# EFM32GG12B810F1024GL112 register map
File version: 4.0.0
CPU: CM4 r0p1, little endian, MPU, FPU, 3 interrupt priority bits
Registers are 32-bit, read-write, reset 0x0 unless marked. A register's access mark holds for its fields unless they carry their own. Offsets are from the block's base; [hi:lo] are bit positions; {n}, {i} and the like mark numbered series; 'fields as' and 'values as' point back to an identical list.

## USB
Base 0x40022000
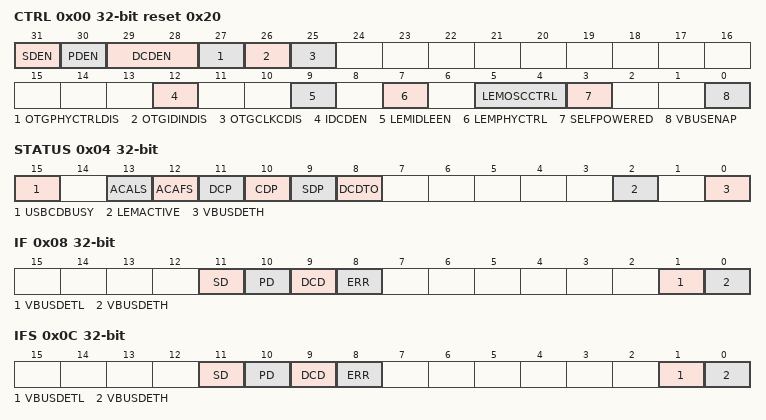
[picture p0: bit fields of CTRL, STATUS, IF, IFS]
0x00 CTRL reset 0x20 — System Control Register
  [31] SDEN — Secondary Detection Enable
  [30] PDEN — Primary Detection Enable
  [29:28] DCDEN — Data Contact Detection Enable
    0=DISABLED (DCD is disabled.); 2=TIMEOUT (Only DCD timeout will be initiated.); 3=ENABLED (Full DCD operation (physical contact and timeout) will be initiated.)
  [27] OTGPHYCTRLDIS — OTG Control Signals to PHY Disable
  [26] OTGIDINDIS — OTG ID Input Disable
  [25] OTGCLKCDIS — OTG CLKC Disable
  [12] IDCDEN — ID Pull-up Enable
  [9] LEMIDLEEN — Low Energy Mode on Bus Idle Enable
  [7] LEMPHYCTRL — Low Energy Mode USB PHY Control
  [5:4] LEMOSCCTRL — Low Energy Mode Oscillator Control
    0=NONE (Low Energy Mode has no effect on neither USBC or USHFRCO.); 1=GATE (The USBC clock is gated when Low Energy Mode is active.)
  [3] SELFPOWERED — PHY Power
  [0] VBUSENAP — VBUSEN Active Polarity
0x04 STATUS ro — System Status Register
  [15] USBCDBUSY — USB Charger Detect Busy
  [13] ACALS — ACA Low Speed TypeB Device
  [12] ACAFS — ACA Full Speed TypeB Device
  [11] DCP — Dedicated Charging Port Detected
  [10] CDP — Charging Downstream Port Detected
  [9] SDP — Standard Downstream Port Detected
  [8] DCDTO — Data Contact Detection Timeout
  [2] LEMACTIVE — Low Energy Mode Active
  [0] VBUSDETH — VBUS Detect High
0x08 IF ro — Interrupt Flag Register
  [11] SD — Secondary Detection Complete Interrupt Flag
  [10] PD — Primary Detection Complete Interrupt Flag
  [9] DCD — Data Contact Detection Complete Interrupt Flag
  [8] ERR — Detection Error Interrupt Flag
  [1] VBUSDETL — VBUS Detect Low Interrupt Flag
  [0] VBUSDETH — VBUS Detect High Interrupt Flag
0x0C IFS wo — Interrupt Flag Set Register
  [11] SD — Set SD Interrupt Flag
  [10] PD — Set PD Interrupt Flag
  [9] DCD — Set DCD Interrupt Flag
  [8] ERR — Set ERR Interrupt Flag
  [1] VBUSDETL — Set VBUSDETL Interrupt Flag
  [0] VBUSDETH — Set VBUSDETH Interrupt Flag
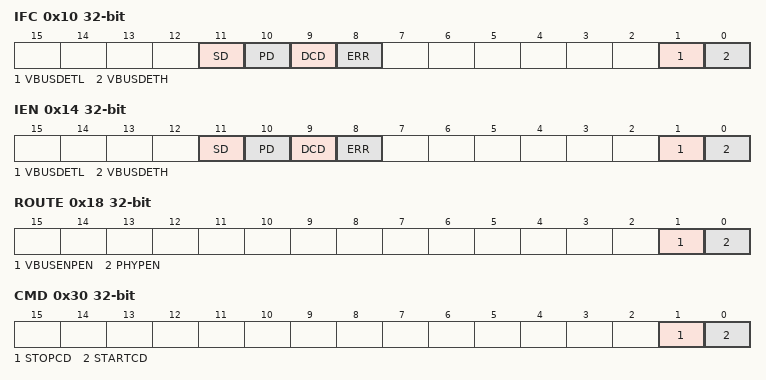
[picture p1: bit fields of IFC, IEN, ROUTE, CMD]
0x10 IFC wo — Interrupt Flag Clear Register
  [11] SD — Clear SD Interrupt Flag
  [10] PD — Clear PD Interrupt Flag
  [9] DCD — Clear DCD Interrupt Flag
  [8] ERR — Clear ERR Interrupt Flag
  [1] VBUSDETL — Clear VBUSDETL Interrupt Flag
  [0] VBUSDETH — Clear VBUSDETH Interrupt Flag
0x14 IEN — Interrupt Enable Register
  [11] SD — SD Interrupt Enable
  [10] PD — PD Interrupt Enable
  [9] DCD — DCD Interrupt Enable
  [8] ERR — ERR Interrupt Enable
  [1] VBUSDETL — VBUSDETL Interrupt Enable
  [0] VBUSDETH — VBUSDETH Interrupt Enable
0x18 ROUTE — I/O Routing Register
  [1] VBUSENPEN — VBUSEN Pin Enable
  [0] PHYPEN — USB PHY Pin Enable
0x2C CDCONF — Charger Detect Configuration Register
  [9:0] DCDTOCONF — DCD Timeout (TDCD_TIMEOUT) Configuration
0x30 CMD wo — Command Register
  [1] STOPCD — Start Charger Detection in Progress
  [0] STARTCD — Start Charger Detection Enabled
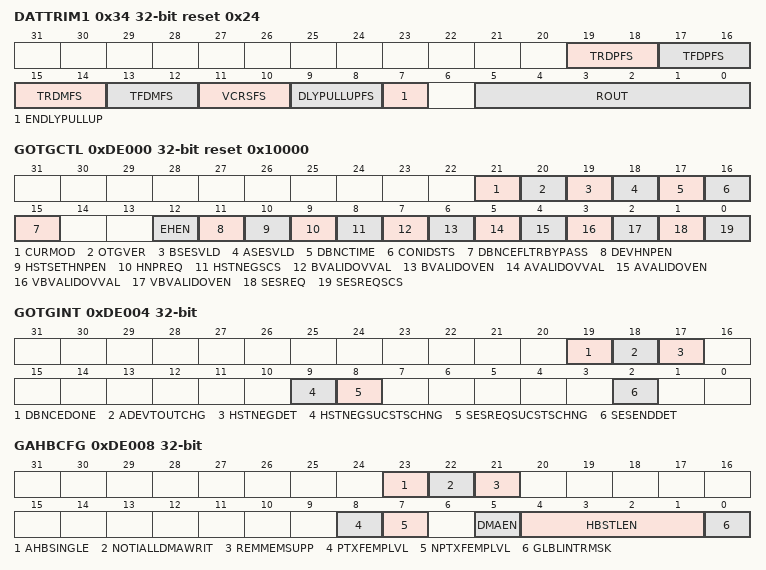
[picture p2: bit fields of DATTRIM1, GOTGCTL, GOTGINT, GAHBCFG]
0x34 DATTRIM1 reset 0x24 — Data TRIM 1 Values for USB DP and DM
  [19:18] TRDPFS — Trim for DP Rise Time in FS
  [17:16] TFDPFS — Trim for DP Fall Time in FS
  [15:14] TRDMFS — Trim for DM Rise Time in FS
  [13:12] TFDMFS — Trim for DM Fall Time in FS
  [11:10] VCRSFS — Trim for Falling Crossover Voltage in FS
  [9:8] DLYPULLUPFS — Trim for Rising Crossover Voltage in FS
  [7] ENDLYPULLUP — Enables Delay of Pull in TX Mode for Both FS and LS
  [5:0] ROUT — Trim for DP and DM Output Impedance for Both FS and LS
0x3C LEMCTRL reset 0x67 — USB LEM Control Register
  [9:0] TIMEBASE — Set the Number of LFC Clk Counts to Form 3ms
0x40 ROUTELOC0 — I/O Routing Location Register
  [5:0] VBUSENPENLOC — I/O Location
    0=LOC0 (Location 0); 1=LOC1 (Location 1); 2=LOC2 (Location 2)
0xDE000 GOTGCTL reset 0x10000 — OTG Control and Status Register
  [21] CURMOD ro — Current Mode of Operation
  [20] OTGVER — OTG Version
  [19] BSESVLD ro — B-Session Valid
  [18] ASESVLD ro — A-Session Valid
  [17] DBNCTIME ro — Long/Short Debounce Time
  [16] CONIDSTS ro — Connector ID Status
  [15] DBNCEFLTRBYPASS — Debounce Filter Bypass
  [12] EHEN — Embedded Host Enable
  [11] DEVHNPEN — Device HNP Enabled
  [10] HSTSETHNPEN — Host Set HNP Enable
  [9] HNPREQ — HNP Request
  [8] HSTNEGSCS ro — Host Negotiation Success
  [7] BVALIDOVVAL — B-Peripheral Session Valid OverrideValue
  [6] BVALIDOVEN — B-Peripheral Session Valid Override Enable
  [5] AVALIDOVVAL — A-Peripheral Session Valid OverrideValue
  [4] AVALIDOVEN — A-Peripheral Session Valid Override Enable
  [3] VBVALIDOVVAL — VBUS Valid OverrideValue
  [2] VBVALIDOVEN — VBUS Valid Override Enable
  [1] SESREQ — Session Request
  [0] SESREQSCS ro — Session Request Success
0xDE004 GOTGINT — OTG Interrupt Register
  [19] DBNCEDONE — Debounce Done
  [18] ADEVTOUTCHG — A-Device Timeout Change
  [17] HSTNEGDET — Host Negotiation Detected
  [9] HSTNEGSUCSTSCHNG — Host Negotiation Success Status Change
  [8] SESREQSUCSTSCHNG — Session Request Success Status Change
  [2] SESENDDET — Session End Detected
0xDE008 GAHBCFG — AHB Configuration Register
  [23] AHBSINGLE — AHB Single Support
  [22] NOTIALLDMAWRIT — Notify All Dma Write Transactions
  [21] REMMEMSUPP — Remote Memory Support
  [8] PTXFEMPLVL — Periodic TxFIFO Empty Level
  [7] NPTXFEMPLVL — Non-Periodic TxFIFO Empty Level
  [5] DMAEN — DMA Enable
  [4:1] HBSTLEN — Burst Length/Type
    0=SINGLE (Single transfer.); 1=INCR (Incrementing burst of unspecified length.); 3=INCR4 (4-beat incrementing burst.); 5=INCR8 (8-beat incrementing burst.); 7=INCR16 (16-beat incrementing burst.)
  [0] GLBLINTRMSK — Global Interrupt Mask
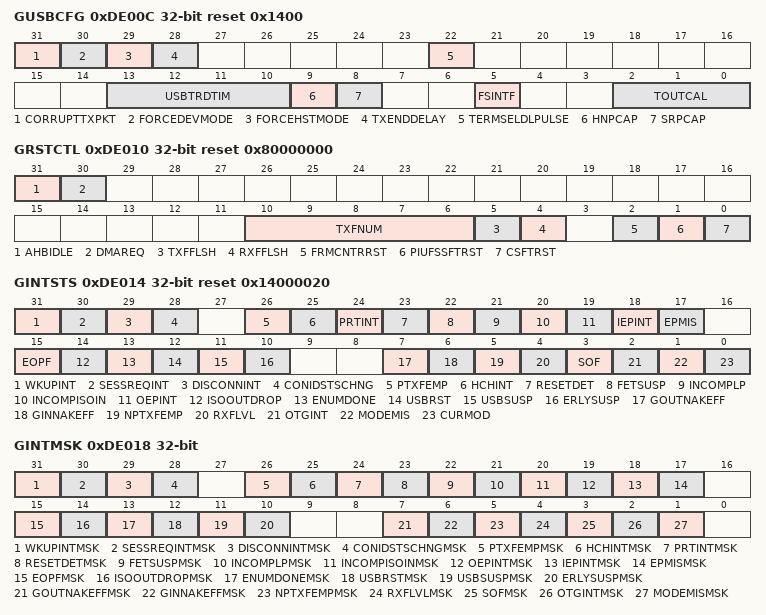
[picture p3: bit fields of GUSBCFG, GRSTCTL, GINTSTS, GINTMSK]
0xDE00C GUSBCFG reset 0x1400 — USB Configuration Register
  [31] CORRUPTTXPKT wo — Corrupt Tx packet (host and device)
  [30] FORCEDEVMODE — Force Device Mode
  [29] FORCEHSTMODE — Force Host Mode
  [28] TXENDDELAY
  [22] TERMSELDLPULSE — TermSel DLine Pulsing Selection
  [13:10] USBTRDTIM — USB Turnaround Time
  [9] HNPCAP — HNP-Capable
  [8] SRPCAP — SRP-Capable
  [5] FSINTF — Full-Speed Serial Interface Select
  [2:0] TOUTCAL — Timeout Calibration (host and device)
0xDE010 GRSTCTL reset 0x80000000 — Reset Register
  [31] AHBIDLE ro — AHB Master Idle
  [30] DMAREQ ro — DMA Request Signal
  [10:6] TXFNUM — TxFIFO Number (host and device)
    0=F0 (Host mode: Non-periodic TxFIFO flush. Device: Tx FIFO 0 flush); 1=F1 (Host mode: Periodic TxFIFO flush. Device: TXFIFO 1 flush.); {v}=F{v} (Device mode: TXFIFO {v} flush.) (v=2..6); 16=FALL (Flush all the transmit FIFOs in device or host mode.)
  [5] TXFFLSH — TxFIFO Flush
  [4] RXFFLSH — RxFIFO Flush
  [2] FRMCNTRRST — Host Frame Counter Reset
  [1] PIUFSSFTRST — PIU FS Dedicated Controller Soft Reset
  [0] CSFTRST — Core Soft Reset (host and device)
0xDE014 GINTSTS reset 0x14000020 — Interrupt Register
  [31] WKUPINT — Resume/Remote Wakeup Detected Interrupt (host and device)
  [30] SESSREQINT — Session Request/New Session Detected Interrupt (host and device)
  [29] DISCONNINT — Disconnect Detected Interrupt (host only)
  [28] CONIDSTSCHNG — Connector ID Status Change (host and device)
  [26] PTXFEMP ro — Periodic TxFIFO Empty (host only)
  [25] HCHINT ro — Host Channels Interrupt (host only)
  [24] PRTINT ro — Host Port Interrupt (host only)
  [23] RESETDET — Reset detected Interrupt (device only)
  [22] FETSUSP — Data Fetch Suspended (device only)
  [21] INCOMPLP — Incomplete Periodic Transfer (device only)
  [20] INCOMPISOIN — Incomplete Isochronous IN Transfer (device only)
  [19] OEPINT ro — OUT Endpoints Interrupt (device only)
  [18] IEPINT ro — IN Endpoints Interrupt (device only)
  [17] EPMIS — Endpoint Mismatch Interrupt (device only)
  [15] EOPF — End of Periodic Frame Interrupt
  [14] ISOOUTDROP — Isochronous OUT Packet Dropped Interrupt (device only)
  [13] ENUMDONE — Enumeration Done (device only)
  [12] USBRST — USB Reset (device only)
  [11] USBSUSP — USB Suspend (device only)
  [10] ERLYSUSP — Early Suspend (device only)
  [7] GOUTNAKEFF ro — Global OUT NAK Effective (device only)
  [6] GINNAKEFF ro — Global IN Non-periodic NAK Effective (device only)
  [5] NPTXFEMP ro — Non-Periodic TxFIFO Empty (host only)
  [4] RXFLVL ro — RxFIFO Non-Empty (host and device)
  [3] SOF — Start of Frame (host and device)
  [2] OTGINT ro — OTG Interrupt (host and device)
  [1] MODEMIS — Mode Mismatch Interrupt (host and device)
  [0] CURMOD ro — Current Mode of Operation (host and device)
0xDE018 GINTMSK — Interrupt Mask Register
  [31] WKUPINTMSK — Resume/Remote Wakeup Detected Interrupt Mask (host and device)
  [30] SESSREQINTMSK — Session Request/New Session Detected Interrupt Mask (host and device)
  [29] DISCONNINTMSK — Disconnect Detected Interrupt Mask (host and device)
  [28] CONIDSTSCHNGMSK — Connector ID Status Change Mask (host and device)
  [26] PTXFEMPMSK — Periodic TxFIFO Empty Mask (host only)
  [25] HCHINTMSK — Host Channels Interrupt Mask (host only)
  [24] PRTINTMSK — Host Port Interrupt Mask (host only)
  [23] RESETDETMSK — Reset detected Interrupt Mask (device only)
  [22] FETSUSPMSK — Data Fetch Suspended Mask (device only)
  [21] INCOMPLPMSK — Incomplete Periodic Transfer Mask (host only)
  [20] INCOMPISOINMSK — Incomplete Isochronous IN Transfer Mask (device only)
  [19] OEPINTMSK — OUT Endpoints Interrupt Mask (device only)
  [18] IEPINTMSK — IN Endpoints Interrupt Mask (device only)
  [17] EPMISMSK — Endpoint Mismatch Interrupt Mask (device only)
  [15] EOPFMSK — End of Periodic Frame Interrupt Mask (device only)
  [14] ISOOUTDROPMSK — Isochronous OUT Packet Dropped Interrupt Mask (device only)
  [13] ENUMDONEMSK — Enumeration Done Mask (device only)
  [12] USBRSTMSK — USB Reset Mask (device only)
  [11] USBSUSPMSK — USB Suspend Mask (device only)
  [10] ERLYSUSPMSK — Early Suspend Mask (device only)
  [7] GOUTNAKEFFMSK — Global OUT NAK Effective Mask (device only)
  [6] GINNAKEFFMSK — Global Non-periodic IN NAK Effective Mask (device only)
  [5] NPTXFEMPMSK — Non-Periodic TxFIFO Empty Mask (host only)
  [4] RXFLVLMSK — Receive FIFO Non-Empty Mask (host and device)
  [3] SOFMSK — Start of Frame Mask (host and device)
  [2] OTGINTMSK — OTG Interrupt Mask (host and device)
  [1] MODEMISMSK — Mode Mismatch Interrupt Mask (host and device)
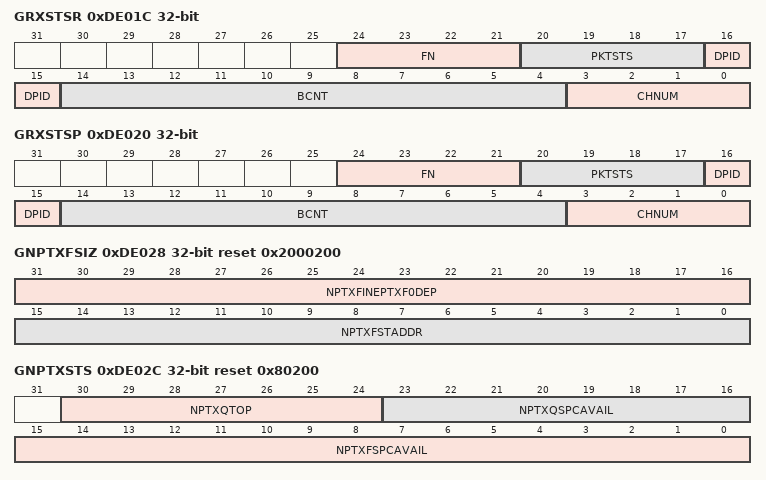
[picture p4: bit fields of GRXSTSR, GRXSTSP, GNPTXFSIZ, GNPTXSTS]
0xDE01C GRXSTSR ro — Receive Status Debug Read Register
  [24:21] FN — Frame Number
  [20:17] PKTSTS — Packet Status
    1=GOUTNAK (Device mode: Global OUT NAK (triggers an interrupt).); 2=PKTRCV (Host mode: IN data packet received. Device mode: OUT data packet received.); 3=XFERCOMPL (Host mode: IN transfer completed (triggers an interrupt). Device mode: OUT transfer completed (triggers an interrupt).); 4=SETUPCOMPL (Device mode: SETUP transaction completed (triggers an interrupt).); 5=TGLERR (Host mode: Data toggle error (triggers an interrupt).); 6=SETUPRCV (Device mode: SETUP data packet received.); 7=CHLT (Host mode: Channel halted (triggers an interrupt).)
  [16:15] DPID — Data PID
    0=DATA0 (DATA0 PID.); 1=DATA1 (DATA1 PID.); 2=DATA2 (DATA2 PID.); 3=MDATA (MDATA PID.)
  [14:4] BCNT — Byte Count
  [3:0] CHNUM — Channel Number
0xDE020 GRXSTSP ro — Receive Status Read /Pop Register
  [24:21] FN — Frame Number
  [20:17] PKTSTS — Packet Status (host or device)
    values as GRXSTSR.PKTSTS
  [16:15] DPID — Data PID (host or device)
    values as GRXSTSR.DPID
  [14:4] BCNT — Byte Count
  [3:0] CHNUM — Channel Number
0xDE024 GRXFSIZ reset 0x200 — Receive FIFO Size Register
  [9:0] RXFDEP — RxFIFO Depth
0xDE028 GNPTXFSIZ reset 0x2000200 — Non-periodic Transmit FIFO Size Register
  [31:16] NPTXFINEPTXF0DEP — Non-periodic TxFIFO Depth (host only) / IN Endpoint TxFIFO 0 Depth (device only)
  [15:0] NPTXFSTADDR — Non-periodic Transmit RAM Start Address
0xDE02C GNPTXSTS ro reset 0x80200 — Non-periodic Transmit FIFO/Queue Status Register
  [30:24] NPTXQTOP — Top of the Non-periodic Transmit Request Queue
  [23:16] NPTXQSPCAVAIL — Non-periodic Transmit Request Queue Space Available
  [15:0] NPTXFSPCAVAIL — Non-periodic TxFIFO Space Avail
0xDE040 GSNPSID ro reset 0x4F54330A — Synopsys ID Register
  [31:0] SYNOPSYSID
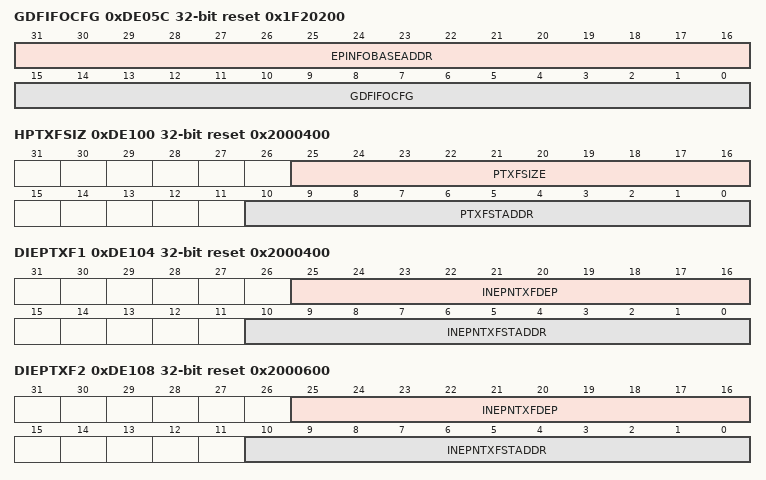
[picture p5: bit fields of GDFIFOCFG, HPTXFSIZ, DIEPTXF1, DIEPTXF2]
0xDE05C GDFIFOCFG reset 0x1F20200 — Global DFIFO Configuration Register
  [31:16] EPINFOBASEADDR, [15:0] GDFIFOCFG
0xDE100 HPTXFSIZ reset 0x2000400 — Host Periodic Transmit FIFO Size Register
  [25:16] PTXFSIZE — Host Periodic TxFIFO Depth
  [10:0] PTXFSTADDR — Host Periodic TxFIFO Start Address
0xDE104 DIEPTXF1 reset 0x2000400 — Device IN Endpoint Transmit FIFO Size Register 1
  [25:16] INEPNTXFDEP — IN Endpoint TxFIFO Depth
  [10:0] INEPNTXFSTADDR — IN Endpoint FIFOn Transmit RAM Start Address
0xDE108 DIEPTXF2 reset 0x2000600 — Device IN Endpoint Transmit FIFO Size Register 2
  fields as DIEPTXF1
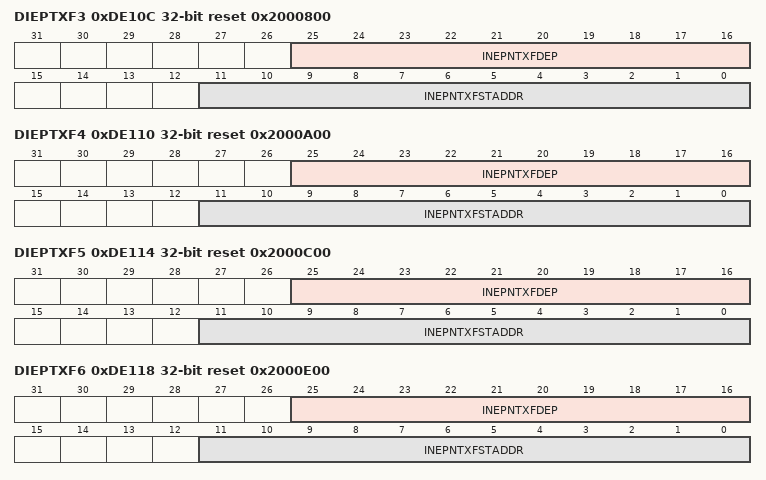
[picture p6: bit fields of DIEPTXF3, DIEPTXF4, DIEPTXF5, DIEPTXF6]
0xDE10C DIEPTXF3 reset 0x2000800 — Device IN Endpoint Transmit FIFO Size Register 3
  [25:16] INEPNTXFDEP — IN Endpoint TxFIFO Depth
  [11:0] INEPNTXFSTADDR — IN Endpoint FIFOn Transmit RAM Start Address
0xDE110 DIEPTXF4 reset 0x2000A00 — Device IN Endpoint Transmit FIFO Size Register 4
  fields as DIEPTXF3
0xDE114 DIEPTXF5 reset 0x2000C00 — Device IN Endpoint Transmit FIFO Size Register 5
  fields as DIEPTXF3
0xDE118 DIEPTXF6 reset 0x2000E00 — Device IN Endpoint Transmit FIFO Size Register 6
  fields as DIEPTXF3
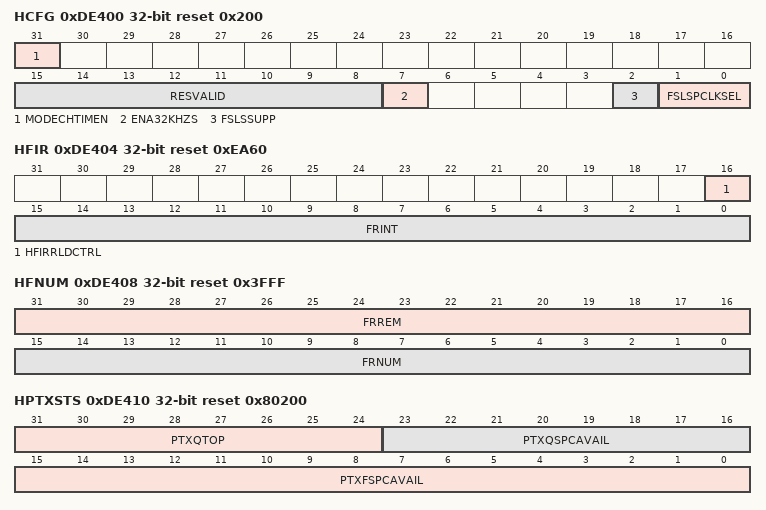
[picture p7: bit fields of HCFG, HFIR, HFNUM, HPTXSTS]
0xDE400 HCFG reset 0x200 — Host Configuration Register
  [31] MODECHTIMEN — Mode Change Time
  [15:8] RESVALID — Resume Validation Period
  [7] ENA32KHZS — Enable 32 kHz Suspend Mode
  [2] FSLSSUPP — FS- and LS-Only Support
  [1:0] FSLSPCLKSEL — FS/LS PHY Clock Select
    1=DIV1 (Internal PHY clock is running at 48 MHz (undivided).); 2=DIV8 (Internal PHY clock is running at 6 MHz (48 MHz divided by 8).)
0xDE404 HFIR reset 0xEA60 — Host Frame Interval Register
  [16] HFIRRLDCTRL — Reload Control
  [15:0] FRINT — Frame Interval
0xDE408 HFNUM ro reset 0x3FFF — Host Frame Number/Frame Time Remaining Register
  [31:16] FRREM — Frame Time Remaining
  [15:0] FRNUM — Frame Number
0xDE410 HPTXSTS ro reset 0x80200 — Host Periodic Transmit FIFO/Queue Status Register
  [31:24] PTXQTOP — Top of the Periodic Transmit Request Queue
  [23:16] PTXQSPCAVAIL — Periodic Transmit Request Queue Space Available
  [15:0] PTXFSPCAVAIL — Periodic Transmit Data FIFO Space Available
0xDE414 HAINT ro — Host All Channels Interrupt Register
  [13:0] HAINT — Channel Interrupt for channel 0 - 13.
0xDE418 HAINTMSK — Host All Channels Interrupt Mask Register
  [13:0] HAINTMSK — Channel Interrupt Mask for channel 0 - 13
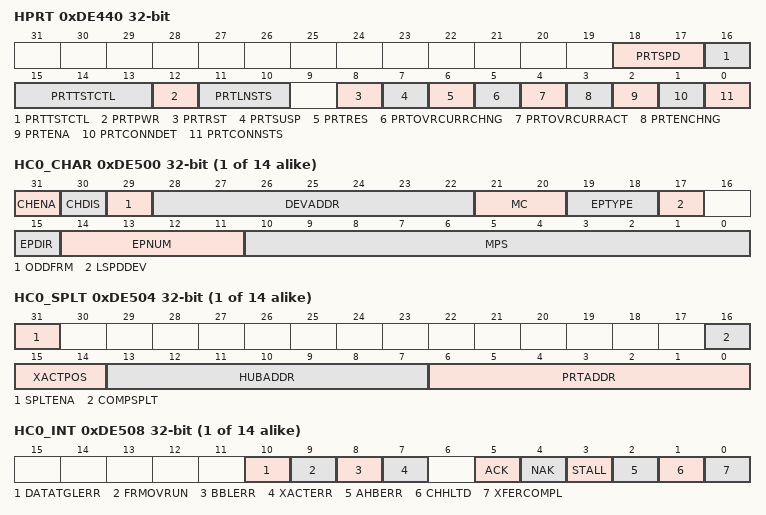
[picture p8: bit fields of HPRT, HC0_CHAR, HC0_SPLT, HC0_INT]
0xDE440 HPRT — Host Port Control and Status Register
  [18:17] PRTSPD ro — Port Speed
    1=FS (Full speed.); 2=LS (Low speed.)
  [16:13] PRTTSTCTL — Port Test Control
    0=DISABLE (Test mode disabled.); 1=J (Test_J mode.); 2=K (Test_K mode.); 3=SE0NAK (Test_SE0_NAK mode.); 4=PACKET (Test_Packet mode.); 5=FORCE (Test_Force_Enable.)
  [12] PRTPWR — Port Power
  [11:10] PRTLNSTS ro — Port Line Status
  [8] PRTRST — Port Reset
  [7] PRTSUSP — Port Suspend
  [6] PRTRES — Port Resume
  [5] PRTOVRCURRCHNG — Port Overcurrent Change
  [4] PRTOVRCURRACT ro — Port Overcurrent Active
  [3] PRTENCHNG — Port Enable/Disable Change
  [2] PRTENA — Port Enable
  [1] PRTCONNDET — Port Connect Detected
  [0] PRTCONNSTS ro — Port Connect Status
{0xDE500+0x20*i} HC{i}_CHAR (i=0..13) — Host Channel x Characteristics Register
  [31] CHENA — Channel Enable
  [30] CHDIS — Channel Disable
  [29] ODDFRM — Odd Frame
  [28:22] DEVADDR — Device Address
  [21:20] MC — Multi Count (MC) / Error Count
  [19:18] EPTYPE — Endpoint Type
    0=CONTROL (Control endpoint.); 1=ISO (Isochronous endpoint.); 2=BULK (Bulk endpoint.); 3=INT (Interrupt endpoint.)
  [17] LSPDDEV — Low-Speed Device
  [15] EPDIR — Endpoint Direction
  [14:11] EPNUM — Endpoint Number
  [10:0] MPS — Maximum Packet Size
{0xDE504+0x20*i} HC{i}_SPLT (i=0..13) — Host Channel x Split Control Register
  [31] SPLTENA — Split Enable
  [16] COMPSPLT — Do Complete Split
  [15:14] XACTPOS — Transaction Position
  [13:7] HUBADDR — Hub Address
  [6:0] PRTADDR — Port Address
{0xDE508+0x20*i} HC{i}_INT (i=0..13) — Host Channel x Interrupt Register
  [10] DATATGLERR — Data Toggle Error
  [9] FRMOVRUN — Frame Overrun
  [8] BBLERR — Babble Error
  [7] XACTERR — Transaction Error
  [5] ACK — ACK Response Received/Transmitted Interrupt
  [4] NAK — NAK Response Received Interrupt
  [3] STALL — STALL Response Received Interrupt
  [2] AHBERR — AHB Error
  [1] CHHLTD — Channel Halted
  [0] XFERCOMPL — Transfer Completed
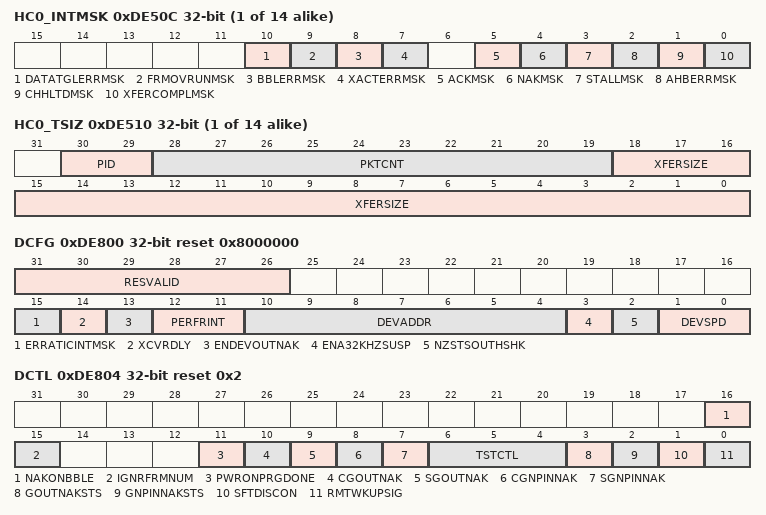
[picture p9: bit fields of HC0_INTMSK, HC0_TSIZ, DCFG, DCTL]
{0xDE50C+0x20*i} HC{i}_INTMSK (i=0..13) — Host Channel x Interrupt Mask Register
  [10] DATATGLERRMSK — Data Toggle Error Mask
  [9] FRMOVRUNMSK — Frame Overrun Mask
  [8] BBLERRMSK — Babble Error Mask
  [7] XACTERRMSK — Transaction Error Mask
  [5] ACKMSK — ACK Response Received/Transmitted Interrupt Mask
  [4] NAKMSK — NAK Response Received Interrupt Mask
  [3] STALLMSK — STALL Response Received Interrupt Mask
  [2] AHBERRMSK — AHB Error Mask
  [1] CHHLTDMSK — Channel Halted Mask
  [0] XFERCOMPLMSK — Transfer Completed Mask
{0xDE510+0x20*i} HC{i}_TSIZ (i=0..13) — Host Channel x Transfer Size Register
  [30:29] PID — The Application Programs This Field With the Type of
    0=DATA0 (DATA0 PID.); 1=DATA2 (DATA2 PID.); 2=DATA1 (DATA1 PID.); 3=MDATA (MDATA (non-control) / SETUP (control) PID.)
  [28:19] PKTCNT — Packet Count
  [18:0] XFERSIZE — Transfer Size
{0xDE514+0x20*i} HC{i}_DMAADDR (i=0..13) — Host Channel x DMA Address Register
  [31:0] DMAADDR — DMA Address
0xDE800 DCFG reset 0x8000000 — Device Configuration Register
  [31:26] RESVALID — Resume Validation Period
  [15] ERRATICINTMSK
  [14] XCVRDLY
  [13] ENDEVOUTNAK — Enable Device OUT NAK
  [12:11] PERFRINT — Periodic Frame Interval
    0=80PCNT (80% of the frame interval.); 1=85PCNT (85% of the frame interval.); 2=90PCNT (90% of the frame interval.); 3=95PCNT (95% of the frame interval.)
  [10:4] DEVADDR — Device Address
  [3] ENA32KHZSUSP — Enable 32 kHz Suspend Mode
  [2] NZSTSOUTHSHK — Non-Zero-Length Status OUT Handshake
  [1:0] DEVSPD — Device Speed
    2=LS (Low speed (PHY clock is 6 MHz). If you select 6 MHz LS mode, you must do a soft reset.); 3=FS (Full speed (PHY clock is 48 MHz).)
0xDE804 DCTL reset 0x2 — Device Control Register
  [16] NAKONBBLE — NAK on Babble Error
  [15] IGNRFRMNUM — Ignore Frame number For Isochronous End points
  [11] PWRONPRGDONE — Power-On Programming Done
  [10] CGOUTNAK wo — Clear Global OUT NAK
  [9] SGOUTNAK wo — Set Global OUT NAK
  [8] CGNPINNAK wo — Clear Global Non-periodic IN NAK
  [7] SGNPINNAK wo — Set Global Non-periodic IN NAK
  [6:4] TSTCTL — Test Control
    values as HPRT.PRTTSTCTL
  [3] GOUTNAKSTS ro — Global OUT NAK Status
  [2] GNPINNAKSTS ro — Global Non-periodic IN NAK Status
  [1] SFTDISCON — Soft Disconnect
  [0] RMTWKUPSIG — Remote Wakeup Signaling
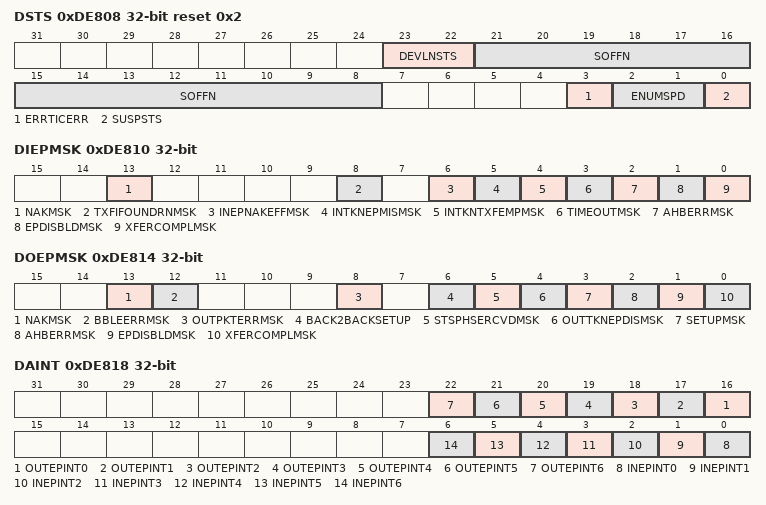
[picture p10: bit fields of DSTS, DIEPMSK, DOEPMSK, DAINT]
0xDE808 DSTS ro reset 0x2 — Device Status Register
  [23:22] DEVLNSTS — Device Line Status
  [21:8] SOFFN — Frame Number of the Received SOF
  [3] ERRTICERR — Erratic Error
  [2:1] ENUMSPD — Enumerated Speed
    2=LS (Low speed (PHY clock is running at 6 MHz).); 3=FS (Full speed (PHY clock is running at 48 MHz).)
  [0] SUSPSTS — Suspend Status
0xDE810 DIEPMSK — Device IN Endpoint Common Interrupt Mask Register
  [13] NAKMSK — NAK interrupt Mask
  [8] TXFIFOUNDRNMSK — Fifo Underrun Mask
  [6] INEPNAKEFFMSK — IN Endpoint NAK Effective Mask
  [5] INTKNEPMISMSK — IN Token received with EP Mismatch Mask
  [4] INTKNTXFEMPMSK — IN Token Received When TxFIFO Empty Mask
  [3] TIMEOUTMSK — Timeout Condition Mask
  [2] AHBERRMSK — AHB Error Mask
  [1] EPDISBLDMSK — Endpoint Disabled Interrupt Mask
  [0] XFERCOMPLMSK — Transfer Completed Interrupt Mask
0xDE814 DOEPMSK — Device OUT Endpoint Common Interrupt Mask Register
  [13] NAKMSK — NAK interrupt Mask
  [12] BBLEERRMSK — Babble Error interrupt Mask
  [8] OUTPKTERRMSK — OUT Packet Error Mask
  [6] BACK2BACKSETUP — Back-to-Back SETUP Packets Received Mask
  [5] STSPHSERCVDMSK — Status Phase Received Mask
  [4] OUTTKNEPDISMSK — OUT Token Received when Endpoint Disabled Mask
  [3] SETUPMSK — SETUP Phase Done Mask
  [2] AHBERRMSK — AHB Error
  [1] EPDISBLDMSK — Endpoint Disabled Interrupt Mask
  [0] XFERCOMPLMSK — Transfer Completed Interrupt Mask
0xDE818 DAINT ro — Device All Endpoints Interrupt Register
  [n+16] OUTEPINT{n} (n=0..6) — OUT Endpoint {n} Interrupt Bit
  [n] INEPINT{n} (n=0..6) — IN Endpoint {n} Interrupt Bit
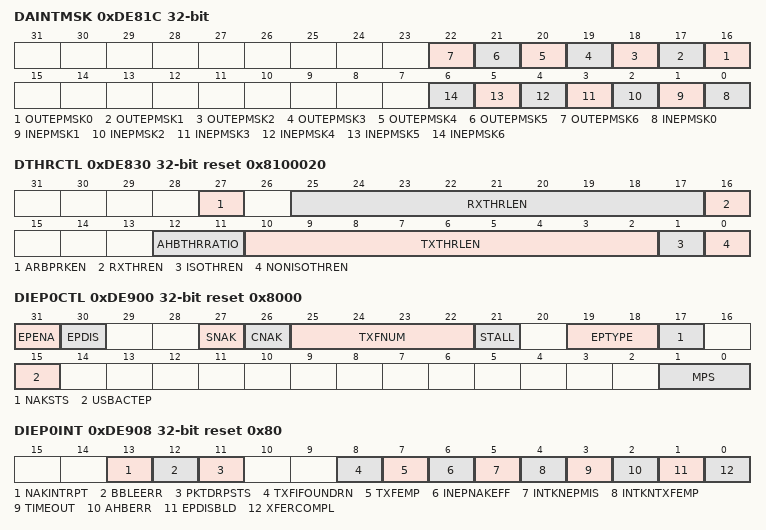
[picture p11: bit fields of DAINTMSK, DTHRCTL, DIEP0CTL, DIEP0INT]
0xDE81C DAINTMSK — Device All Endpoints Interrupt Mask Register
  [n+16] OUTEPMSK{n} (n=0..6) — OUT Endpoint {n} Interrupt mask Bit
  [n] INEPMSK{n} (n=0..6) — IN Endpoint {n} Interrupt mask Bit
0xDE828 DVBUSDIS reset 0x17D7 — Device VBUS Discharge Time Register
  [15:0] DVBUSDIS — Device VBUS Discharge Time
0xDE82C DVBUSPULSE reset 0x5B8 — Device VBUS Pulsing Time Register
  [11:0] DVBUSPULSE — Device VBUS Pulsing Time
0xDE830 DTHRCTL reset 0x8100020 — Device Threshold Control Register
  [27] ARBPRKEN — Arbiter Parking Enable
  [25:17] RXTHRLEN — Receive Threshold Length
  [16] RXTHREN — Receive Threshold Enable
  [12:11] AHBTHRRATIO — AHB Threshold Ratio
    0=DIV1 (AHB threshold = MAC threshold.); 1=DIV2 (AHB threshold = MAC threshold / 2.); 2=DIV4 (AHB threshold = MAC threshold / 4.); 3=DIV8 (AHB threshold = MAC threshold / 8.)
  [10:2] TXTHRLEN — Transmit Threshold Length
  [1] ISOTHREN — ISO IN Endpoints Threshold Enable
  [0] NONISOTHREN — Non-ISO IN Endpoints Threshold Enable
0xDE834 DIEPEMPMSK — Device IN Endpoint FIFO Empty Interrupt Mask Register
  [15:0] INEPTXFEMPMSK — IN EP Tx FIFO Empty Interrupt Mask Bits
0xDE900 DIEP0CTL reset 0x8000 — Device Control IN Endpoint 0 Control Register
  [31] EPENA — Endpoint Enable
  [30] EPDIS — Endpoint Disable
  [27] SNAK wo — Set NAK
  [26] CNAK wo — Clear NAK
  [25:22] TXFNUM — TxFIFO Number
  [21] STALL — Handshake
  [19:18] EPTYPE ro — Endpoint Type
  [17] NAKSTS ro — NAK Status
  [15] USBACTEP ro — USB Active Endpoint
  [1:0] MPS — Maximum Packet Size
    0=64B (64 bytes.); 1=32B (32 bytes.); 2=16B (16 bytes.); 3=8B (8 bytes.)
0xDE908 DIEP0INT reset 0x80 — Device IN Endpoint 0 Interrupt Register
  [13] NAKINTRPT — NAK Interrupt
  [12] BBLEERR — Babble Interrupt
  [11] PKTDRPSTS — Packet Drop Status
  [8] TXFIFOUNDRN — Fifo Underrun
  [7] TXFEMP ro — Transmit FIFO Empty
  [6] INEPNAKEFF — IN Endpoint NAK Effective
  [5] INTKNEPMIS — IN Token Received with EP Mismatch
  [4] INTKNTXFEMP — IN Token Received When TxFIFO is Empty
  [3] TIMEOUT — Timeout Condition
  [2] AHBERR — AHB Error
  [1] EPDISBLD — Endpoint Disabled Interrupt
  [0] XFERCOMPL — Transfer Completed Interrupt
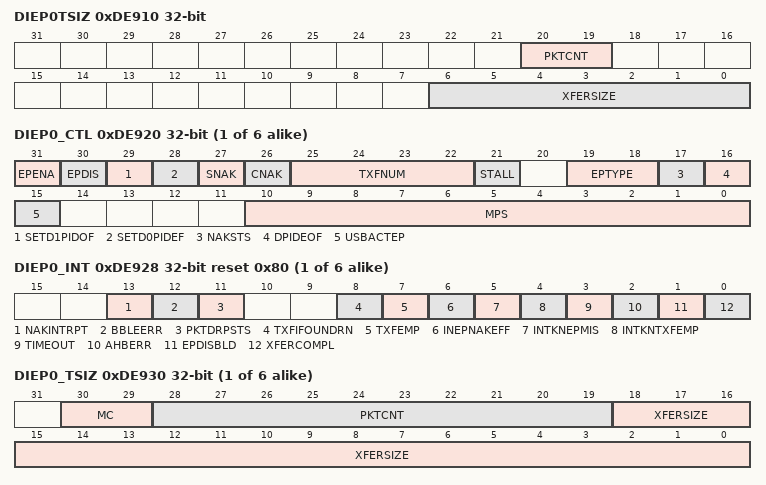
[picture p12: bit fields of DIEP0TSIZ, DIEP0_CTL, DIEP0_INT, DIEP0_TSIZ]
0xDE910 DIEP0TSIZ — Device IN Endpoint 0 Transfer Size Register
  [20:19] PKTCNT — Packet Count
  [6:0] XFERSIZE — Transfer Size
0xDE914 DIEP0DMAADDR — Device IN Endpoint 0 DMA Address Register
  [31:0] DMAADDR
0xDE918 DIEP0TXFSTS ro reset 0x200 — Device IN Endpoint Transmit FIFO Status Register 0
  [15:0] SPCAVAIL — IN Endpoint TxFIFO Space Avail
{0xDE920+0x20*i} DIEP{i}_CTL (i=0..5) — Device Control IN Endpoint x+1 Control Register
  [31] EPENA — Endpoint Enable
  [30] EPDIS — Endpoint Disable
  [29] SETD1PIDOF wo — Set DATA1 PID / Odd Frame
  [28] SETD0PIDEF wo — Set DATA0 PID / Even Frame
  [27] SNAK wo — Set NAK
  [26] CNAK wo — Clear NAK
  [25:22] TXFNUM — TxFIFO Number
  [21] STALL — Handshake
  [19:18] EPTYPE — Endpoint Type
    0=CONTROL (Control Endpoint.); 1=ISO (Isochronous Endpoint.); 2=BULK (Bulk Endpoint.); 3=INT (Interrupt Endpoint.)
  [17] NAKSTS ro — NAK Status
  [16] DPIDEOF ro — Endpoint Data PID / Even or Odd Frame
  [15] USBACTEP — USB Active Endpoint
  [10:0] MPS — Maximum Packet Size
{0xDE928+0x20*i} DIEP{i}_INT reset 0x80 (i=0..5) — Device IN Endpoint x+1 Interrupt Register
  fields as DIEP0INT
{0xDE930+0x20*i} DIEP{i}_TSIZ (i=0..5) — Device IN Endpoint x+1 Transfer Size Register
  [30:29] MC — Multi Count
  [28:19] PKTCNT — Packet Count
  [18:0] XFERSIZE — Transfer Size
{0xDE934+0x20*i} DIEP{i}_DMAADDR (i=0..5) — Device IN Endpoint x+1 DMA Address Register
{0xDE938+0x20*i} DIEP{i}_DTXFSTS ro reset 0x200 (i=0..5) — Device IN Endpoint Transmit FIFO Status Register 1
  [15:0] SPCAVAIL — IN Endpoint TxFIFO Space Avail
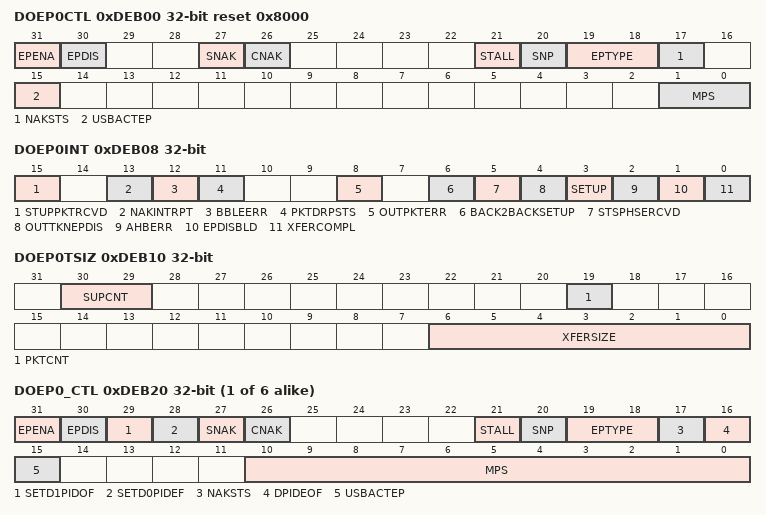
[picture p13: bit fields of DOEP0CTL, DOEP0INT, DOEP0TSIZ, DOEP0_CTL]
0xDEB00 DOEP0CTL reset 0x8000 — Device Control OUT Endpoint 0 Control Register
  [31] EPENA — Endpoint Enable
  [30] EPDIS ro — Endpoint Disable
  [27] SNAK wo — Set NAK
  [26] CNAK wo — Clear NAK
  [21] STALL — Handshake
  [20] SNP — Snoop Mode
  [19:18] EPTYPE ro — Endpoint Type
  [17] NAKSTS ro — NAK Status
  [15] USBACTEP ro — USB Active Endpoint
  [1:0] MPS ro — Maximum Packet Size
    values as DIEP0CTL.MPS
0xDEB08 DOEP0INT — Device OUT Endpoint 0 Interrupt Register
  [15] STUPPKTRCVD
  [13] NAKINTRPT — NAK Interrupt
  [12] BBLEERR — NAK Interrupt
  [11] PKTDRPSTS — Packet Drop Status
  [8] OUTPKTERR — OUT Packet Error
  [6] BACK2BACKSETUP — Back-to-Back SETUP Packets Received
  [5] STSPHSERCVD — Status Phase Received For Control Write
  [4] OUTTKNEPDIS — OUT Token Received When Endpoint Disabled
  [3] SETUP — Setup Phase Done
  [2] AHBERR — AHB Error
  [1] EPDISBLD — Endpoint Disabled Interrupt
  [0] XFERCOMPL — Transfer Completed Interrupt
0xDEB10 DOEP0TSIZ — Device OUT Endpoint 0 Transfer Size Register
  [30:29] SUPCNT — SETUP Packet Count
  [19] PKTCNT — Packet Count
  [6:0] XFERSIZE — Transfer Size
0xDEB14 DOEP0DMAADDR — Device OUT Endpoint 0 DMA Address Register
  [31:0] DMAADDR
{0xDEB20+0x20*i} DOEP{i}_CTL (i=0..5) — Device Control OUT Endpoint x+1 Control Register
  [31] EPENA — Endpoint Enable
  [30] EPDIS — Endpoint Disable
  [29] SETD1PIDOF wo — Set DATA1 PID / Odd Frame
  [28] SETD0PIDEF wo — Set DATA0 PID / Even Frame
  [27] SNAK wo — Set NAK
  [26] CNAK wo — Clear NAK
  [21] STALL — STALL Handshake
  [20] SNP — Snoop Mode
  [19:18] EPTYPE — Endpoint Type
    values as DIEP0_CTL.EPTYPE
  [17] NAKSTS ro — NAK Status
  [16] DPIDEOF ro — Endpoint Data PID / Even-odd Frame
  [15] USBACTEP — USB Active Endpoint
  [10:0] MPS — Maximum Packet Size
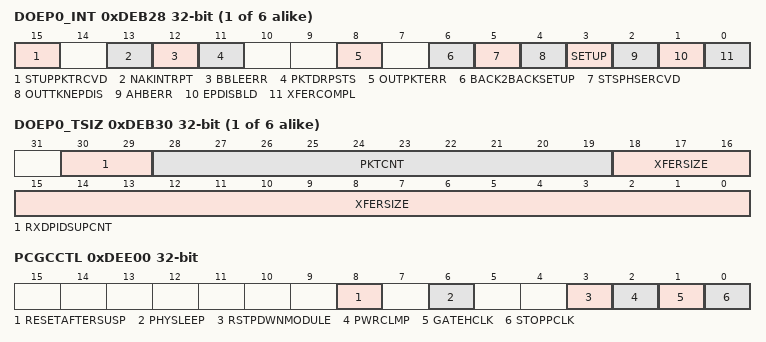
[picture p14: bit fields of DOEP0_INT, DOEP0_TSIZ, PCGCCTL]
{0xDEB28+0x20*i} DOEP{i}_INT (i=0..5) — Device OUT Endpoint x+1 Interrupt Register
  [15] STUPPKTRCVD
  [13] NAKINTRPT — NAK Interrupt
  [12] BBLEERR — Babble Error
  [11] PKTDRPSTS — Packet Drop Status
  [8] OUTPKTERR — OUT Packet Error
  [6] BACK2BACKSETUP — Back-to-Back SETUP Packets Received
  [5] STSPHSERCVD — Status Phase Received For Control Write
  [4] OUTTKNEPDIS — OUT Token Received When Endpoint Disabled
  [3] SETUP — Setup Phase Done
  [2] AHBERR — AHB Error
  [1] EPDISBLD — Endpoint Disabled Interrupt
  [0] XFERCOMPL — Transfer Completed Interrupt
{0xDEB30+0x20*i} DOEP{i}_TSIZ (i=0..5) — Device OUT Endpoint x+1 Transfer Size Register
  [30:29] RXDPIDSUPCNT ro — Receive Data PID / SETUP Packet Count
    0=DATA0 (DATA0 PID.); 1=DATA2 (DATA2 PID / 1 Packet.); 2=DATA1 (DATA1 PID / 2 Packets.); 3=MDATA (MDATA PID / 3 Packets.)
  [28:19] PKTCNT — Packet Count
  [18:0] XFERSIZE — Transfer Size
{0xDEB34+0x20*i} DOEP{i}_DMAADDR (i=0..5) — Device OUT Endpoint x+1 DMA Address Register
0xDEE00 PCGCCTL — Power and Clock Gating Control Register
  [8] RESETAFTERSUSP ro — Reset after suspend
  [6] PHYSLEEP ro — PHY In Sleep
  [3] RSTPDWNMODULE — Reset Power-Down Modules
  [2] PWRCLMP — Power Clamp
  [1] GATEHCLK
  [0] STOPPCLK — Stop PHY clock

## Notices in the file
# License
Copyright 2021 Silicon Laboratories Inc. www.silabs.com
SPDX-License-Identifier: Zlib
The licensor of this software is Silicon Laboratories Inc.
This software is provided 'as-is', without any express or implied
warranty. In no event will the authors be held liable for any damages
arising from the use of this software.
Permission is granted to anyone to use this software for any purpose,
including commercial applications, and to alter it and redistribute it
freely, subject to the following restrictions:
1. The origin of this software must not be misrepresented; you must not
claim that you wrote the original software. If you use this software
in a product, an acknowledgment in the product documentation would be
appreciated but is not required.
2. Altered source versions must be plainly marked as such, and must not be
misrepresented as being the original software.
3. This notice may not be removed or altered from any source distribution.
